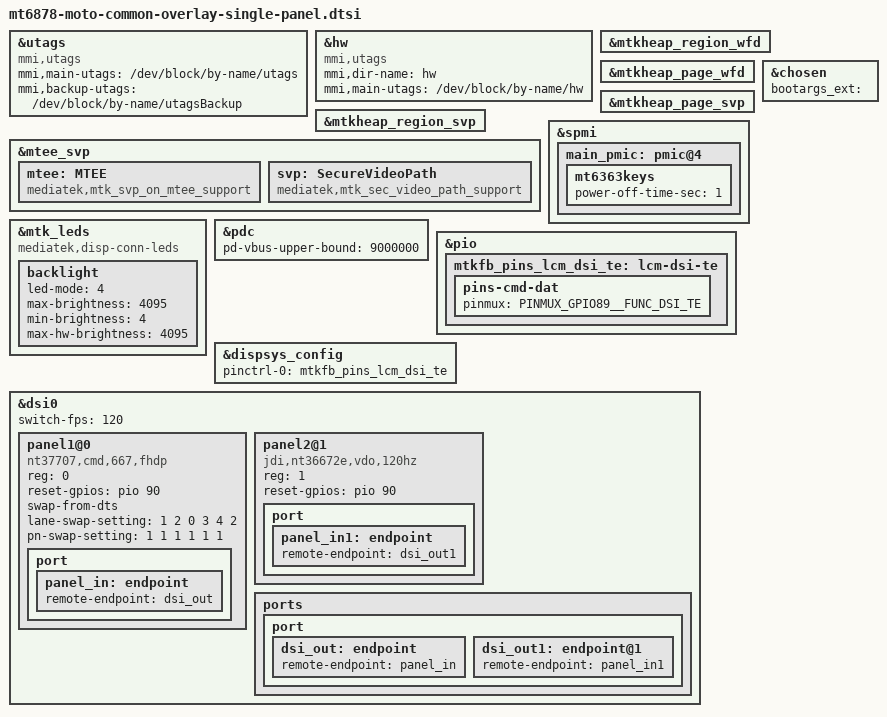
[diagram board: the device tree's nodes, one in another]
// SPDX-License-Identifier: (GPL-2.0 OR MIT)
/*
 * Copyright (C) 2022 MediaTek Inc.
 */
/dts-v1/;
/plugin/;
#include <dt-bindings/interrupt-controller/arm-gic.h>
#include <dt-bindings/interrupt-controller/irq.h>
#include <dt-bindings/phy/phy.h>
#include <dt-bindings/pinctrl/mt6878-pinfunc.h>
#include "mediatek/carrier-channel-ids.dtsi"

#if 0
#include <dt-bindings/pinctrl/mt6897-pinfunc.h>
#endif

&utags {
	compatible = "mmi,utags";
	mmi,main-utags = "/dev/block/by-name/utags";
	mmi,backup-utags = "/dev/block/by-name/utagsBackup";
};

&hw {
	compatible = "mmi,utags";
	mmi,dir-name = "hw";
	mmi,main-utags = "/dev/block/by-name/hw";
};

/* WFD */
&mtkheap_region_wfd {
status = "ok";
};

&mtkheap_page_wfd {
status = "ok";
};

/* SVP */
&mtkheap_page_svp {
status = "ok";
};

&mtkheap_region_svp {
status = "ok";
};


&mtee_svp {
	mtee: MTEE {
		compatible = "mediatek,mtk_svp_on_mtee_support";
	};
	svp: SecureVideoPath {
		compatible = "mediatek,mtk_sec_video_path_support";
	};
};

/*
long powerkey reset setting

#   power-off-time-sec :
#   0      : 8 sec
#   1      : 11 sec
#   2      : 2 sec
#   3      : 5 sec
#
*/
&spmi {
	main_pmic: pmic@4 {
		mt6363keys: mt6363keys {
			power-off-time-sec = <1>;
		};
	};
};

&chosen {
bootargs_ext = "";
};

&mtk_leds {
	compatible = "mediatek,disp-conn-leds";

	backlight {
		led-mode = <4>;
		max-brightness = <4095>;
		min-brightness = <4>;
		max-hw-brightness = <4095>;
	};
};

&pdc {
	pd-vbus-upper-bound = <9000000>;
};

#if 0

&connfem {
/* Enable epa_elna node to support Wifi & BT ePA/eLNA FEM on customer load */
#if 0
	epa-elna {
		parts = <&wlan7207h &wlan7207c>;
		wifi {
			flags-0 {
				open-loop;
			};
		};
		bt {
			flags-0 {
				/* choose one of: epa-elna/epa/elna/bypass */
				epa-elna;
			};
		};
	};
#endif
};

/* GPS GPIO standardization start */
&pio {
	gps_pins_default: gps-default {
	};
	gps_l1_lna_pins_ol: gps-l1-lna0 {
		pins-cmd-dat {
			pinmux = <PINMUX_GPIO143__FUNC_GPIO143>;
			output-low;
		};
	};
	gps_l1_lna_pins_dsp_ctrl: gps-l1-lna1 {
		pins-cmd-dat {
			pinmux = <PINMUX_GPIO143__FUNC_GPS_L1_ELNA_EN>;
		};
	};
	gps_l1_lna_pins_oh: gps-l1-lna2 {
		pins-cmd-dat {
			pinmux = <PINMUX_GPIO143__FUNC_GPIO143>;
			output-high;
		};
	};
	gps_l5_lna_pins_ol: gps-l5-lna0 {
		pins-cmd-dat {
			pinmux = <PINMUX_GPIO144__FUNC_GPIO144>;
			output-low;
		};
	};
	gps_l5_lna_pins_dsp_ctrl: gps-l5-lna1 {
		pins-cmd-dat {
			pinmux = <PINMUX_GPIO144__FUNC_GPS_L5_ELNA_EN>;
		};
	};
	gps_l5_lna_pins_oh: gps-l5-lna2 {
		pins-cmd-dat {
			pinmux = <PINMUX_GPIO144__FUNC_GPIO144>;
			output-high;
		};
	};
};
&gps {
	pinctrl-names = "default",
		"gps_l1_lna_disable",
		"gps_l1_lna_dsp_ctrl",
		"gps_l1_lna_enable",
		"gps_l5_lna_disable",
		"gps_l5_lna_dsp_ctrl",
		"gps_l5_lna_enable";
	pinctrl-0 = <&gps_pins_default>;
	pinctrl-1 = <&gps_l1_lna_pins_ol>;
	pinctrl-2 = <&gps_l1_lna_pins_dsp_ctrl>;
	pinctrl-3 = <&gps_l1_lna_pins_oh>;
	pinctrl-4 = <&gps_l5_lna_pins_ol>;
	pinctrl-5 = <&gps_l5_lna_pins_dsp_ctrl>;
	pinctrl-6 = <&gps_l5_lna_pins_oh>;
	status = "okay";
};
/* GPS GPIO standardization end */

#endif

&pio {
	mtkfb_pins_lcm_dsi_te: lcm-dsi-te {
		pins-cmd-dat {
			pinmux = <PINMUX_GPIO89__FUNC_DSI_TE>;
		};
	};
};

&dispsys_config {
	pinctrl-names = "mode_te_te";
	pinctrl-0 = <&mtkfb_pins_lcm_dsi_te>;
	status = "okay";
};

&dsi0 {
	status = "okay";
	#address-cells = <1>;
	#size-cells = <0>;
	switch-fps = <120>;
	panel1@0 {
		/delete-property/ compatible;
		/delete-property/ pm-enable-gpios;
		/delete-property/ gate-ic;

		compatible = "nt37707,cmd,667,fhdp";
		reg = <0>;
		reset-gpios = <&pio 90 0>;
		swap-from-dts;
		lane-swap-setting = <1 2 0 3 4 2>;
		pn-swap-setting = <1 1 1 1 1 1>;
		pinctrl-names = "default";
		port {
			panel_in: endpoint {
				remote-endpoint = <&dsi_out>;
			};
		};
	};
	panel2@1 {
		/delete-property/ compatible;
		/delete-property/ pm-enable-gpios;
		/delete-property/ gate-ic;

		compatible = "jdi,nt36672e,vdo,120hz";
		reg = <1>;
		reset-gpios = <&pio 90 0>;
		pinctrl-names = "default";
		port {
			panel_in1: endpoint {
				remote-endpoint = <&dsi_out1>;
			};
		};
	};
	ports {
		port {
			dsi_out: endpoint {
				remote-endpoint = <&panel_in>;
			};

			dsi_out1: endpoint@1 {
				remote-endpoint = <&panel_in1>;
			};
		};

	};
};

//#include <k6878v1_64_flip/cust.dtsi>
//#include "mediatek/cust_mt6878_touch_flip.dtsi"
//#include "mediatek/cust_mt6878_camera_v4l2.dtsi"
#include "mediatek/cust_k6878_connfem.dtsi"
/*End of this file, DO NOT ADD ANYTHING HERE*/
